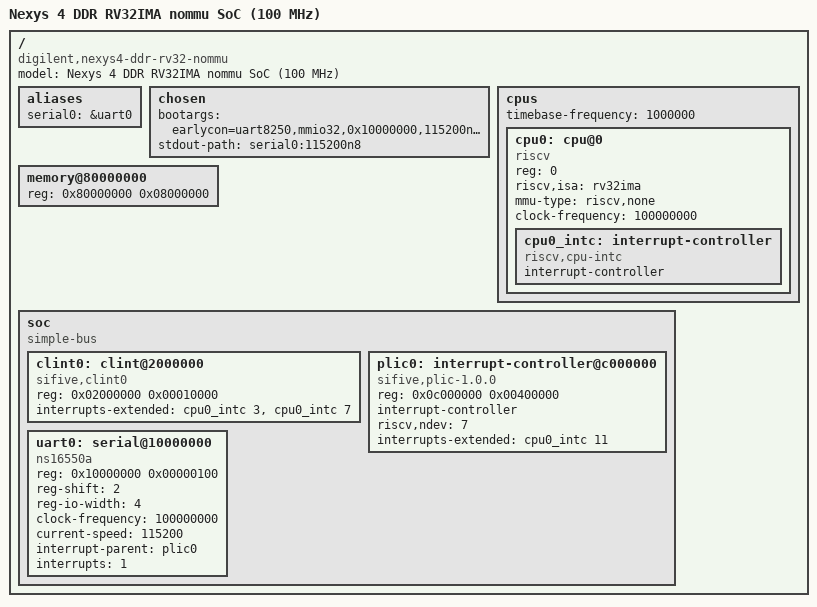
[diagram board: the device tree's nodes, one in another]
// ============================================================================
// nexys4_rv32_nommu.dts — 路线 A 备用 M-mode nommu Linux 设备树 (可选)
// ----------------------------------------------------------------------------
// 供仅验证最小 M-mode nommu 内核时使用；主力标准 Linux 请优先使用 nexys4_rv32_sv32.dts。
// ============================================================================

/dts-v1/;

/ {
	#address-cells = <1>;
	#size-cells = <1>;
	compatible = "digilent,nexys4-ddr-rv32-nommu";
	model = "Nexys 4 DDR RV32IMA nommu SoC (100 MHz)";

	aliases {
		serial0 = &uart0;
	};

	chosen {
		bootargs = "earlycon=uart8250,mmio32,0x10000000,115200n8 console=ttyS0,115200n8 rdinit=/init";
		stdout-path = "serial0:115200n8";
	};

	cpus {
		#address-cells = <1>;
		#size-cells = <0>;
		timebase-frequency = <1000000>;

		cpu0: cpu@0 {
			device_type = "cpu";
			compatible = "riscv";
			reg = <0>;
			riscv,isa = "rv32ima";
			mmu-type = "riscv,none";
			clock-frequency = <100000000>;

			cpu0_intc: interrupt-controller {
				#interrupt-cells = <1>;
				compatible = "riscv,cpu-intc";
				interrupt-controller;
			};
		};
	};

	memory@80000000 {
		device_type = "memory";
		reg = <0x80000000 0x08000000>;
	};

	soc {
		#address-cells = <1>;
		#size-cells = <1>;
		compatible = "simple-bus";
		ranges;

		clint0: clint@2000000 {
			compatible = "sifive,clint0", "riscv,clint0";
			reg = <0x02000000 0x00010000>;
			interrupts-extended = <&cpu0_intc 3 &cpu0_intc 7>;
		};

		plic0: interrupt-controller@c000000 {
			#interrupt-cells = <1>;
			#address-cells = <0>;
			compatible = "sifive,plic-1.0.0", "riscv,plic0";
			reg = <0x0c000000 0x00400000>;
			interrupt-controller;
			riscv,ndev = <7>;
			interrupts-extended = <&cpu0_intc 11>;
		};

		uart0: serial@10000000 {
			compatible = "ns16550a";
			reg = <0x10000000 0x00000100>;
			reg-shift = <2>;
			reg-io-width = <4>;
			clock-frequency = <100000000>;
			current-speed = <115200>;
			interrupt-parent = <&plic0>;
			interrupts = <1>;
		};
	};
};
